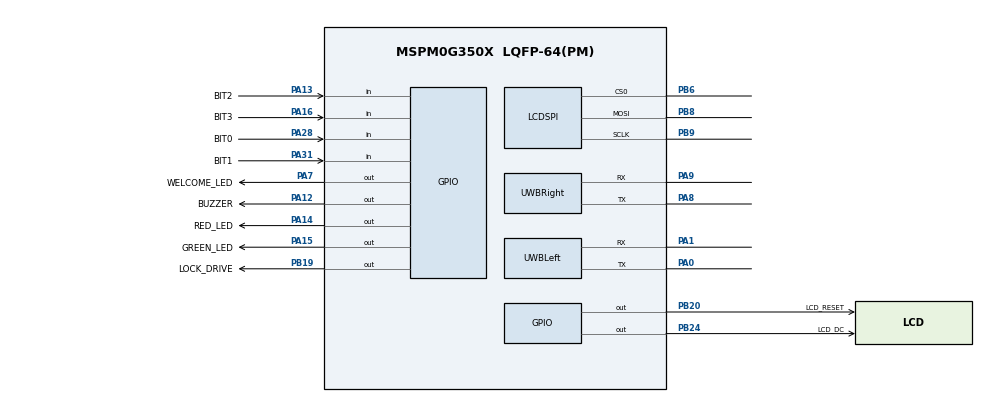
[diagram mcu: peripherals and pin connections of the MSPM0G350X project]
/**
 * @cliArgs --device "MSPM0G350X" --part "Default" --package "LQFP-64(PM)" --product "mspm0_sdk@2.10.00.04"
 * @versions {"tool":"1.26.2+4477"}
 */

const SYSCTL       = scripting.addModule("/ti/driverlib/SYSCTL");
const UART         = scripting.addModule("/ti/driverlib/UART", {}, false);
const GPIO         = scripting.addModule("/ti/driverlib/GPIO", {}, false);
const SPI          = scripting.addModule("/ti/driverlib/SPI", {}, false);
const Board        = scripting.addModule("/ti/driverlib/Board", {}, false);
const UWBRight     = UART.addInstance();
const UWBLeft      = UART.addInstance();
const LCDSPI       = SPI.addInstance();
const DipSwitches  = GPIO.addInstance();
const LockOutputsA = GPIO.addInstance();
const LockOutputsB = GPIO.addInstance();

const divider9       = system.clockTree["UDIV"];
divider9.divideValue = 2;

const gate7  = system.clockTree["MFCLKGATE"];
gate7.enable = true;

const multiplier2         = system.clockTree["PLL_QDIV"];
multiplier2.multiplyValue = 4;

const mux4       = system.clockTree["EXHFMUX"];
mux4.inputSelect = "EXHFMUX_XTAL";

const mux8       = system.clockTree["HSCLKMUX"];
mux8.inputSelect = "HSCLKMUX_SYSPLL0";

const mux12       = system.clockTree["SYSPLLMUX"];
mux12.inputSelect = "zSYSPLLMUX_HFCLK";

const pinFunction4        = system.clockTree["HFXT"];
pinFunction4.inputFreq    = 40;
pinFunction4.enable       = true;
pinFunction4.HFXTStartup  = 10;
pinFunction4.HFCLKMonitor = true;

SYSCTL.forceDefaultClkConfig = true;
SYSCTL.clockTreeEn           = true;

UWBRight.$name                            = "UWB_RIGHT";
UWBRight.targetBaudRate                   = 921600;
UWBRight.enableFIFO                       = true;
UWBRight.rxFifoThreshold                  = "DL_UART_RX_FIFO_LEVEL_ONE_ENTRY";
UWBRight.enabledInterrupts                = ["RX"];
UWBRight.peripheral.$assign               = "UART1";
UWBRight.peripheral.rxPin.$assign         = "PA9";
UWBRight.peripheral.txPin.$assign         = "PA8";

UWBLeft.$name                            = "UWB_LEFT";
UWBLeft.targetBaudRate                   = 921600;
UWBLeft.enableFIFO                       = true;
UWBLeft.rxFifoThreshold                  = "DL_UART_RX_FIFO_LEVEL_ONE_ENTRY";
UWBLeft.enabledInterrupts                = ["RX"];
UWBLeft.peripheral.$assign               = "UART0";
UWBLeft.peripheral.rxPin.$assign         = "PA1";
UWBLeft.peripheral.txPin.$assign         = "PA0";

LCDSPI.$name                      = "LCD_SPI";
LCDSPI.mode                       = "CONTROLLER";
LCDSPI.spiClkSrc                  = "BUSCLK";
LCDSPI.targetBitRate              = 8000000;
LCDSPI.frameFormat                = "MOTO4";
LCDSPI.polarity                   = "0";
LCDSPI.phase                      = "0";
LCDSPI.dataSize                   = 8;
LCDSPI.bitOrder                   = "MSB";
LCDSPI.chipSelect                 = ["0"];
LCDSPI.direction                  = "PICO";
LCDSPI.peripheral.$assign         = "SPI1";
LCDSPI.peripheral.sclkPin.$assign = "PB9";
LCDSPI.peripheral.mosiPin.$assign = "PB8";
LCDSPI.peripheral.cs0Pin.$assign  = "PB6";
LCDSPI.cs0PinConfig.enableConfig  = true;
LCDSPI.cs0PinConfig.internalResistor = "PULL_UP";

DipSwitches.$name = "DIP_SWITCHES";
DipSwitches.associatedPins.create(4);
DipSwitches.associatedPins[0].$name            = "BIT0";
DipSwitches.associatedPins[0].direction        = "INPUT";
DipSwitches.associatedPins[0].internalResistor = "PULL_UP";
DipSwitches.associatedPins[0].pin.$assign      = "PA28";
DipSwitches.associatedPins[1].$name            = "BIT1";
DipSwitches.associatedPins[1].direction        = "INPUT";
DipSwitches.associatedPins[1].internalResistor = "PULL_UP";
DipSwitches.associatedPins[1].pin.$assign      = "PA31";
DipSwitches.associatedPins[2].$name            = "BIT2";
DipSwitches.associatedPins[2].direction        = "INPUT";
DipSwitches.associatedPins[2].internalResistor = "PULL_UP";
DipSwitches.associatedPins[2].pin.$assign      = "PA13";
DipSwitches.associatedPins[3].$name            = "BIT3";
DipSwitches.associatedPins[3].direction        = "INPUT";
DipSwitches.associatedPins[3].internalResistor = "PULL_UP";
DipSwitches.associatedPins[3].pin.$assign      = "PA16";

LockOutputsA.$name = "LOCK_OUTPUTS_A";
LockOutputsA.associatedPins.create(4);
LockOutputsA.associatedPins[0].$name        = "RED_LED";
LockOutputsA.associatedPins[0].direction    = "OUTPUT";
LockOutputsA.associatedPins[0].initialValue = "SET";
LockOutputsA.associatedPins[0].pin.$assign  = "PA14";
LockOutputsA.associatedPins[1].$name        = "GREEN_LED";
LockOutputsA.associatedPins[1].direction    = "OUTPUT";
LockOutputsA.associatedPins[1].initialValue = "CLEARED";
LockOutputsA.associatedPins[1].pin.$assign  = "PA15";
LockOutputsA.associatedPins[2].$name        = "BUZZER";
LockOutputsA.associatedPins[2].direction    = "OUTPUT";
LockOutputsA.associatedPins[2].initialValue = "SET";
LockOutputsA.associatedPins[2].pin.$assign  = "PA12";
LockOutputsA.associatedPins[3].$name        = "WELCOME_LED";
LockOutputsA.associatedPins[3].direction    = "OUTPUT";
LockOutputsA.associatedPins[3].initialValue = "CLEARED";
LockOutputsA.associatedPins[3].pin.$assign  = "PA7";

LockOutputsB.$name = "LOCK_OUTPUTS_B";
LockOutputsB.associatedPins.create(3);
LockOutputsB.associatedPins[0].$name        = "LOCK_DRIVE";
LockOutputsB.associatedPins[0].direction    = "OUTPUT";
LockOutputsB.associatedPins[0].initialValue = "CLEARED";
LockOutputsB.associatedPins[0].pin.$assign  = "PB19";
LockOutputsB.associatedPins[1].$name        = "LCD_RESET";
LockOutputsB.associatedPins[1].direction    = "OUTPUT";
LockOutputsB.associatedPins[1].initialValue = "SET";
LockOutputsB.associatedPins[1].pin.$assign  = "PB20";
LockOutputsB.associatedPins[2].$name        = "LCD_DC";
LockOutputsB.associatedPins[2].direction    = "OUTPUT";
LockOutputsB.associatedPins[2].initialValue = "SET";
LockOutputsB.associatedPins[2].pin.$assign  = "PB24";

pinFunction4.peripheral.$suggestSolution           = "SYSCTL";
pinFunction4.peripheral.hfxInPin.$suggestSolution  = "PA5";
pinFunction4.peripheral.hfxOutPin.$suggestSolution = "PA6";
Board.peripheral.$suggestSolution                  = "DEBUGSS";
Board.peripheral.swclkPin.$suggestSolution         = "PA20";
Board.peripheral.swdioPin.$suggestSolution         = "PA19";
